# STM32F746ZGY7 register map
File version: 1.0
Registers are 32-bit, access not given, reset 0x0 unless marked. A register's access mark holds for its fields unless they carry their own. Offsets are from the block's base; [hi:lo] are bit positions; {n}, {i} and the like mark numbered series.

## USART2
Base 0x40004400
Same registers: USART3 0x40004800, UART4 0x40004C00, UART5 0x40005000, UART7 0x40007800, UART8 0x40007C00, USART1 0x40011000, USART6 0x40011400
0x00 CR1
  [27] EOBIE, [26] RTOIE, [25:21] DEAT, [20:16] DEDT, [15] OVER8, [14] CMIE, [13] MME, [28:12] M, [11] WAKE, [10] PCE, [9] PS, [8] PEIE, [7] TXEIE, [6] TCIE, [5] RXNEIE, [4] IDLEIE, [3] TE, [2] RE, [0] UE
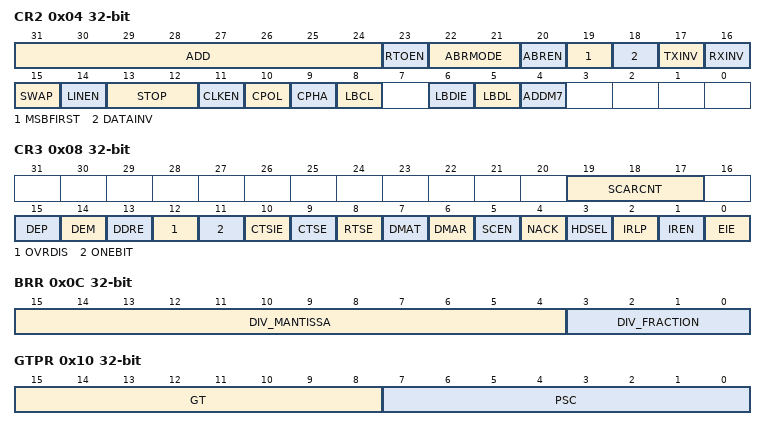
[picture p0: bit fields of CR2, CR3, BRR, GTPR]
0x04 CR2
  [31:24] ADD, [23] RTOEN, [22:21] ABRMODE, [20] ABREN, [19] MSBFIRST, [18] DATAINV, [17] TXINV, [16] RXINV, [15] SWAP, [14] LINEN, [13:12] STOP, [11] CLKEN, [10] CPOL, [9] CPHA, [8] LBCL, [6] LBDIE, [5] LBDL, [4] ADDM7
0x08 CR3
  [19:17] SCARCNT, [15] DEP, [14] DEM, [13] DDRE, [12] OVRDIS, [11] ONEBIT, [10] CTSIE, [9] CTSE, [8] RTSE, [7] DMAT, [6] DMAR, [5] SCEN, [4] NACK, [3] HDSEL, [2] IRLP, [1] IREN, [0] EIE
0x0C BRR
  [15:4] DIV_MANTISSA, [3:0] DIV_FRACTION
0x10 GTPR
  [15:8] GT, [7:0] PSC
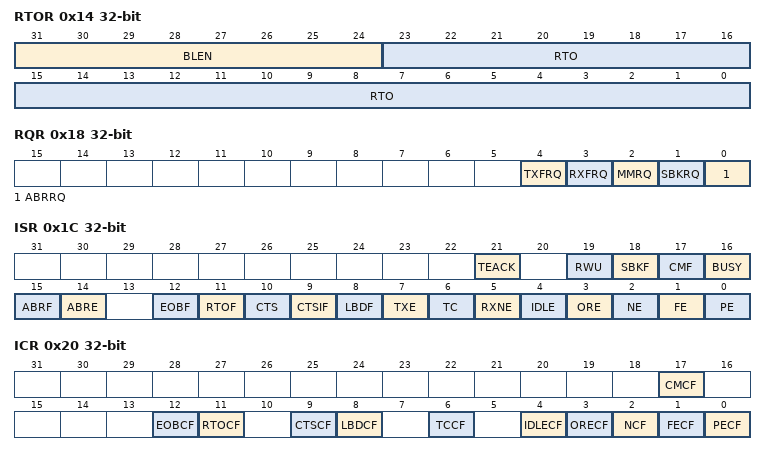
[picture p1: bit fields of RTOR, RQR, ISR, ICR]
0x14 RTOR
  [31:24] BLEN, [23:0] RTO
0x18 RQR
  [4] TXFRQ, [3] RXFRQ, [2] MMRQ, [1] SBKRQ, [0] ABRRQ
0x1C ISR
  [21] TEACK, [19] RWU, [18] SBKF, [17] CMF, [16] BUSY, [15] ABRF, [14] ABRE, [12] EOBF, [11] RTOF, [10] CTS, [9] CTSIF, [8] LBDF, [7] TXE, [6] TC, [5] RXNE, [4] IDLE, [3] ORE, [2] NE, [1] FE, [0] PE
0x20 ICR
  [17] CMCF, [12] EOBCF, [11] RTOCF, [9] CTSCF, [8] LBDCF, [6] TCCF, [4] IDLECF, [3] ORECF, [2] NCF, [1] FECF, [0] PECF
0x24 RDR
  [8:0] RDR
0x28 TDR
  [8:0] TDR

## I2C1
Base 0x40005400
Same registers: I2C2 0x40005800, I2C3 0x40005C00, I2C4 0x40006000
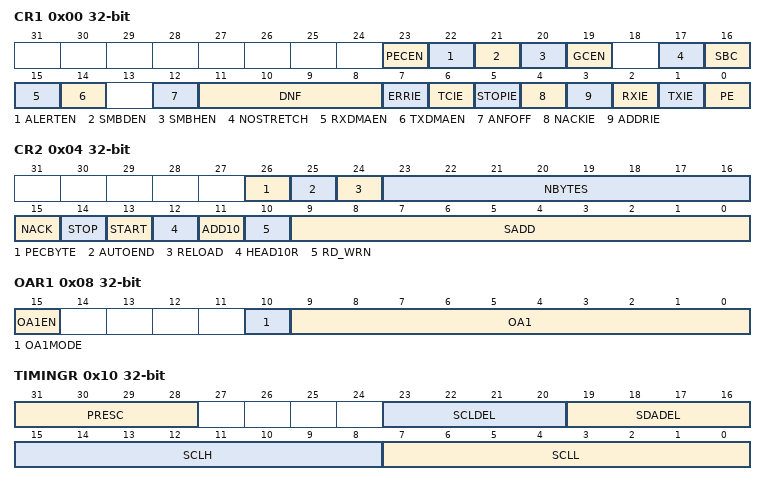
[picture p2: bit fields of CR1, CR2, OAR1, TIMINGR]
0x00 CR1
  [23] PECEN, [22] ALERTEN, [21] SMBDEN, [20] SMBHEN, [19] GCEN, [17] NOSTRETCH, [16] SBC, [15] RXDMAEN, [14] TXDMAEN, [12] ANFOFF, [11:8] DNF, [7] ERRIE, [6] TCIE, [5] STOPIE, [4] NACKIE, [3] ADDRIE, [2] RXIE, [1] TXIE, [0] PE
0x04 CR2
  [26] PECBYTE, [25] AUTOEND, [24] RELOAD, [23:16] NBYTES, [15] NACK, [14] STOP, [13] START, [12] HEAD10R, [11] ADD10, [10] RD_WRN, [9:0] SADD
0x08 OAR1
  [15] OA1EN, [10] OA1MODE, [9:0] OA1
0x0C OAR2
  [15] OA2EN, [10] OA2MASK04, [10:9] OA2MASK06, [10:8] OA2MSK, [7:1] OA2
0x10 TIMINGR
  [31:28] PRESC, [23:20] SCLDEL, [19:16] SDADEL, [15:8] SCLH, [7:0] SCLL
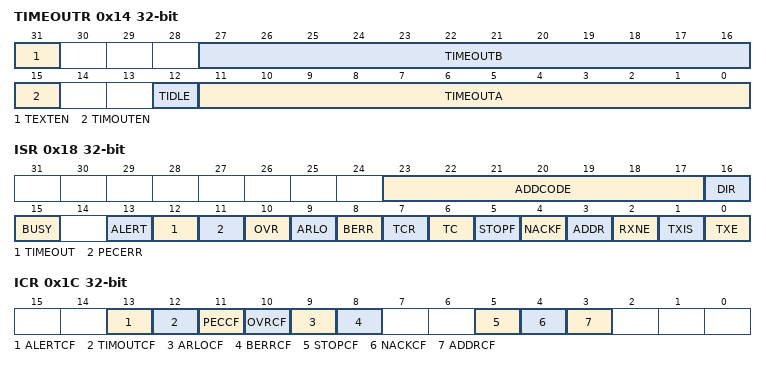
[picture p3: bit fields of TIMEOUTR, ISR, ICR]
0x14 TIMEOUTR
  [31] TEXTEN, [27:16] TIMEOUTB, [15] TIMOUTEN, [12] TIDLE, [11:0] TIMEOUTA
0x18 ISR
  [23:17] ADDCODE, [16] DIR, [15] BUSY, [13] ALERT, [12] TIMEOUT, [11] PECERR, [10] OVR, [9] ARLO, [8] BERR, [7] TCR, [6] TC, [5] STOPF, [4] NACKF, [3] ADDR, [2] RXNE, [1] TXIS, [0] TXE
0x1C ICR
  [13] ALERTCF, [12] TIMOUTCF, [11] PECCF, [10] OVRCF, [9] ARLOCF, [8] BERRCF, [5] STOPCF, [4] NACKCF, [3] ADDRCF
0x20 PECR
  [7:0] PEC
0x24 RXDR
  [7:0] RXDATA
0x28 TXDR
  [7:0] TXDATA

## CEC
Base 0x40006C00
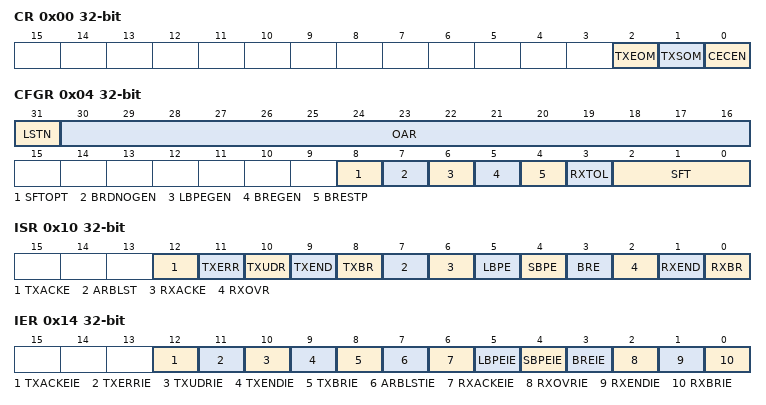
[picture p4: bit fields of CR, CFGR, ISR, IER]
0x00 CR
  [2] TXEOM, [1] TXSOM, [0] CECEN
0x04 CFGR
  [31] LSTN, [30:16] OAR, [8] SFTOPT, [7] BRDNOGEN, [6] LBPEGEN, [5] BREGEN, [4] BRESTP, [3] RXTOL, [2:0] SFT
0x08 TXDR
  [7:0] TXD
0x0C RXDR
  [7:0] RXD
0x10 ISR
  [12] TXACKE, [11] TXERR, [10] TXUDR, [9] TXEND, [8] TXBR, [7] ARBLST, [6] RXACKE, [5] LBPE, [4] SBPE, [3] BRE, [2] RXOVR, [1] RXEND, [0] RXBR
0x14 IER
  [12] TXACKEIE, [11] TXERRIE, [10] TXUDRIE, [9] TXENDIE, [8] TXBRIE, [7] ARBLSTIE, [6] RXACKEIE, [5] LBPEIE, [4] SBPEIE, [3] BREIE, [2] RXOVRIE, [1] RXENDIE, [0] RXBRIE

## PWR
Base 0x40007000
0x00 CR1
  [19:18] UDEN, [17] ODSWEN, [16] ODEN, [15:14] VOS, [13] ADCDC1, [11] MRUDS, [10] LPUDS, [9] FPDS, [8] DBP, [7] PLS_LEV4, [7:6] PLS_LEV6, [7:5] PLS_LEV7, [4] PVDE, [3] CSBF, [1] PDDS, [0] LPDS
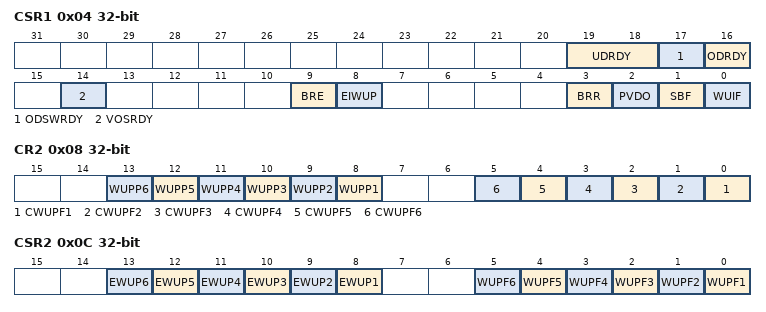
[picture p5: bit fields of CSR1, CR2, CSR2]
0x04 CSR1
  [19:18] UDRDY, [17] ODSWRDY, [16] ODRDY, [14] VOSRDY, [9] BRE, [8] EIWUP, [3] BRR, [2] PVDO, [1] SBF, [0] WUIF
0x08 CR2
  [n+7] WUPP{n} (n=1..6), [n-1] CWUPF{n} (n=1..6)
0x0C CSR2
  [n+7] EWUP{n} (n=1..6), [n-1] WUPF{n} (n=1..6)

## DAC1
Base 0x40007400
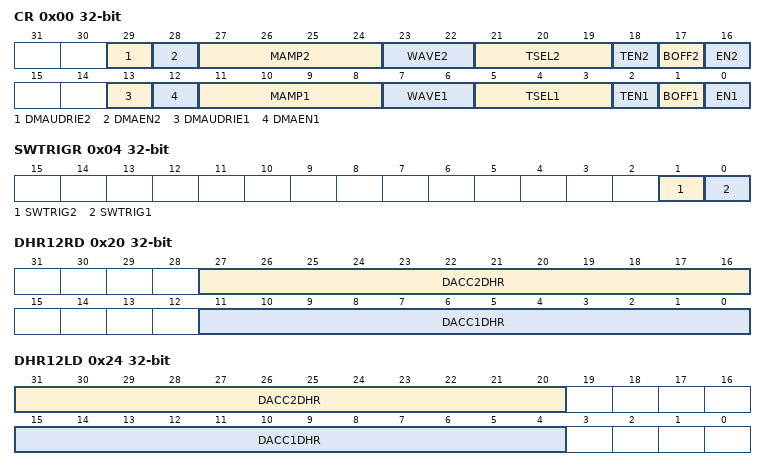
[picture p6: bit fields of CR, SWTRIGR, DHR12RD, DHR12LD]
0x00 CR
  [29] DMAUDRIE2, [28] DMAEN2, [27:24] MAMP2, [23:22] WAVE2, [21:19] TSEL2, [18] TEN2, [17] BOFF2, [16] EN2, [13] DMAUDRIE1, [12] DMAEN1, [11:8] MAMP1, [7:6] WAVE1, [5:3] TSEL1, [2] TEN1, [1] BOFF1, [0] EN1
0x04 SWTRIGR
  [1] SWTRIG2, [0] SWTRIG1
0x08 DHR12R1
  [11:0] DACC1DHR
0x0C DHR12L1
  [15:4] DACC1DHR
0x10 DHR8R1
  [7:0] DACC1DHR
0x14 DHR12R2
  [11:0] DACC2DHR
0x18 DHR12L2
  [15:4] DACC2DHR
0x1C DHR8R2
  [7:0] DACC2DHR
0x20 DHR12RD
  [27:16] DACC2DHR, [11:0] DACC1DHR
0x24 DHR12LD
  [31:20] DACC2DHR, [15:4] DACC1DHR
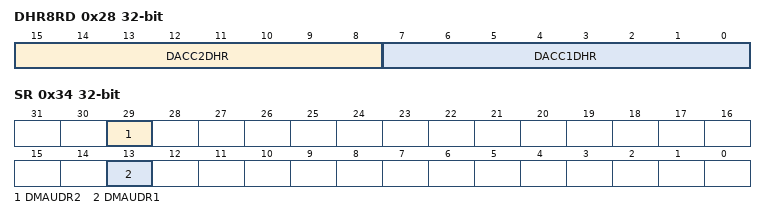
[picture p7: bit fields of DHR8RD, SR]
0x28 DHR8RD
  [15:8] DACC2DHR, [7:0] DACC1DHR
0x2C DOR1
  [11:0] DACC1DOR
0x30 DOR2
  [11:0] DACC2DOR
0x34 SR
  [29] DMAUDR2, [13] DMAUDR1
